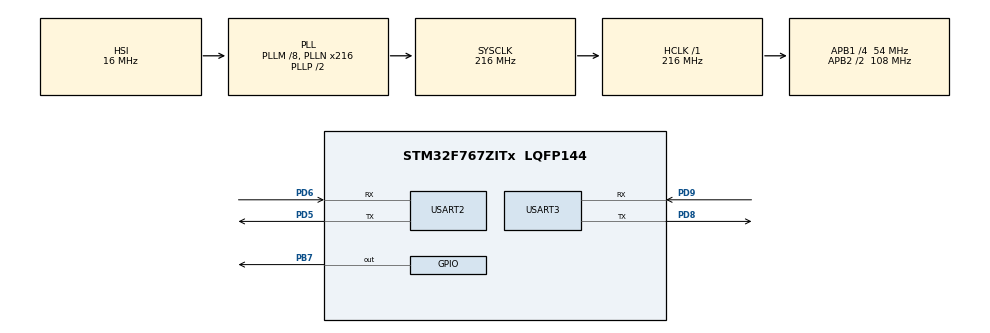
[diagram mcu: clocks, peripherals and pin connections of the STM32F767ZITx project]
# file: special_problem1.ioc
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Mcu.Family=STM32F7
Mcu.Name=STM32F767ZITx
Mcu.Package=LQFP144
NVIC.PriorityGroup=NVIC_PRIORITYGROUP_4
PB7.Signal=GPIO_Output
PD5.Mode=Asynchronous
PD5.Signal=USART2_TX
PD6.Mode=Asynchronous
PD6.Signal=USART2_RX
PD8.Mode=Asynchronous
PD8.Signal=USART3_TX
PD9.Mode=Asynchronous
PD9.Signal=USART3_RX
ProjectManager.HeapSize=0x200
ProjectManager.StackSize=0x400
ProjectManager.TargetToolchain=STM32CubeIDE
RCC.AHBFreq_Value=216000000
RCC.APB1CLKDivider=RCC_HCLK_DIV4
RCC.APB1Freq_Value=54000000
RCC.APB1TimFreq_Value=108000000
RCC.APB2CLKDivider=RCC_HCLK_DIV2
RCC.APB2Freq_Value=108000000
RCC.APB2TimFreq_Value=216000000
RCC.CortexFreq_Value=216000000
RCC.HCLKFreq_Value=216000000
RCC.HSE_VALUE=25000000
RCC.HSI_VALUE=16000000
RCC.LSE_VALUE=32768
RCC.PLLM=8
RCC.PLLN=216
RCC.SYSCLKFreq_VALUE=216000000
RCC.SYSCLKSource=RCC_SYSCLKSOURCE_PLLCLK
RCC.USBFreq_Value=216000000
RCC.VCOOutputFreq_Value=432000000
USART2.VirtualMode-Asynchronous=VM_ASYNC
USART3.VirtualMode-Asynchronous=VM_ASYNC
board=custom

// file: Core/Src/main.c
/* USER CODE BEGIN Header */
/**
  ******************************************************************************
  * @file           : main.c
  * @brief          : Main program body
  ******************************************************************************
  * @attention
  *
  * Copyright (c) 2023 STMicroelectronics.
  * All rights reserved.
  *
  * This software is licensed under terms that can be found in the LICENSE file
  * in the root directory of this software component.
  * If no LICENSE file comes with this software, it is provided AS-IS.
  *
  ******************************************************************************
  */
/* USER CODE END Header */
#include "main.h"
#include "usart.h"
#include "gpio.h"

/* USER CODE BEGIN Includes */
#include "string.h"
/* USER CODE END Includes */

/* USER CODE BEGIN PV */
char ch ;
//char ch1[];

/* USER CODE END PV */

void SystemClock_Config(void);

int main(void)
{

  /* MCU Configuration--------------------------------------------------------*/

  /* Reset of all peripherals, Initializes the Flash interface and the Systick. */
  HAL_Init();

  /* Configure the system clock */
  SystemClock_Config();

  /* Initialize all configured peripherals */
  MX_GPIO_Init();
  MX_USART2_UART_Init();
  MX_USART3_UART_Init();

  /* Infinite loop */
  /* USER CODE BEGIN WHILE */
  while (1)
  {
		while (__HAL_UART_GET_FLAG(&huart2, UART_FLAG_RXNE) == RESET) {}
	  HAL_UART_Receive(&huart2, (uint8_t*) &ch,1, 1000);
	  if(ch == 'A'){
		  HAL_GPIO_WritePin(GPIOB, GPIO_PIN_7,SET);
		  HAL_UART_Transmit(&huart3, (uint8_t*) &ch,1, 1000);
	  }
	  else{

		  HAL_GPIO_WritePin(GPIOB, GPIO_PIN_7,RESET);
		  HAL_UART_Transmit(&huart3, (uint8_t*)"n",1, 1000);
	  }
	  HAL_Delay(2000);
    /* USER CODE END WHILE */

  }
}

void SystemClock_Config(void)
{
  RCC_OscInitTypeDef RCC_OscInitStruct = {0};
  RCC_ClkInitTypeDef RCC_ClkInitStruct = {0};

  /** Configure the main internal regulator output voltage
  */
  __HAL_RCC_PWR_CLK_ENABLE();
  __HAL_PWR_VOLTAGESCALING_CONFIG(PWR_REGULATOR_VOLTAGE_SCALE1);

  /** Initializes the RCC Oscillators according to the specified parameters
  * in the RCC_OscInitTypeDef structure.
  */
  RCC_OscInitStruct.OscillatorType = RCC_OSCILLATORTYPE_HSI;
  RCC_OscInitStruct.HSIState = RCC_HSI_ON;
  RCC_OscInitStruct.HSICalibrationValue = RCC_HSICALIBRATION_DEFAULT;
  RCC_OscInitStruct.PLL.PLLState = RCC_PLL_ON;
  RCC_OscInitStruct.PLL.PLLSource = RCC_PLLSOURCE_HSI;
  RCC_OscInitStruct.PLL.PLLM = 8;
  RCC_OscInitStruct.PLL.PLLN = 216;
  RCC_OscInitStruct.PLL.PLLP = RCC_PLLP_DIV2;
  RCC_OscInitStruct.PLL.PLLQ = 2;
  RCC_OscInitStruct.PLL.PLLR = 2;
  if (HAL_RCC_OscConfig(&RCC_OscInitStruct) != HAL_OK)
  {
    Error_Handler();
  }

  /** Activate the Over-Drive mode
  */
  if (HAL_PWREx_EnableOverDrive() != HAL_OK)
  {
    Error_Handler();
  }

  /** Initializes the CPU, AHB and APB buses clocks
  */
  RCC_ClkInitStruct.ClockType = RCC_CLOCKTYPE_HCLK|RCC_CLOCKTYPE_SYSCLK
                              |RCC_CLOCKTYPE_PCLK1|RCC_CLOCKTYPE_PCLK2;
  RCC_ClkInitStruct.SYSCLKSource = RCC_SYSCLKSOURCE_PLLCLK;
  RCC_ClkInitStruct.AHBCLKDivider = RCC_SYSCLK_DIV1;
  RCC_ClkInitStruct.APB1CLKDivider = RCC_HCLK_DIV4;
  RCC_ClkInitStruct.APB2CLKDivider = RCC_HCLK_DIV2;

  if (HAL_RCC_ClockConfig(&RCC_ClkInitStruct, FLASH_LATENCY_7) != HAL_OK)
  {
    Error_Handler();
  }
}

/* USER CODE BEGIN 4 */
//void Hal_UART_RxCpltCallback(UART_HandleTypeDef *huart)
//{
//	HAL_UART_Receive_IT(&huart2,(uint8_t*) &ch1,strlen(ch1));
//	HAL_UART_Transmit(&huart3,(uint8_t*) &ch1,strlen(ch1),1000);
//	HAL_Delay(2000);
//	HAL_GPIO_WritePin(GPIOB, GPIO_PIN_7,SET);
//	HAL_Delay(2000);
//	HAL_GPIO_WritePin(GPIOB, GPIO_PIN_7,RESET);
//}
/* USER CODE END 4 */

void Error_Handler(void)
{
  __disable_irq();
  while (1)
  {
  }
}
